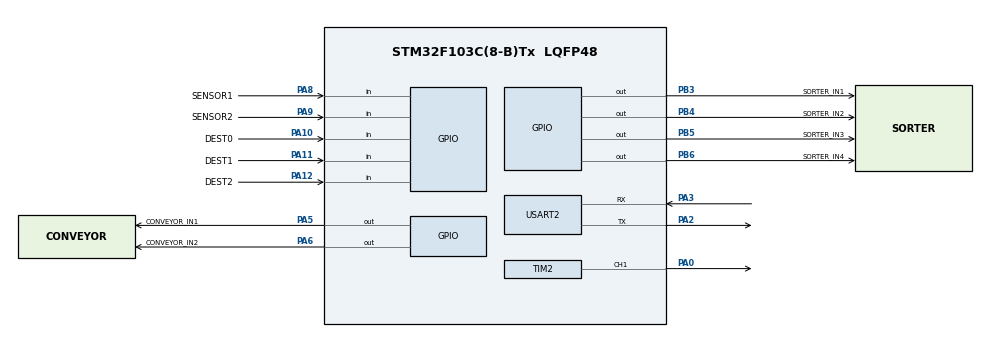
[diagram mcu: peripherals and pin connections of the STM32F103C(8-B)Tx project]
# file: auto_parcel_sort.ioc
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Dma.Request0=USART2_RX
Dma.USART2_RX.0.Direction=DMA_PERIPH_TO_MEMORY
Dma.USART2_RX.0.Instance=DMA1_Channel6
Dma.USART2_RX.0.MemDataAlignment=DMA_MDATAALIGN_BYTE
Dma.USART2_RX.0.MemInc=DMA_MINC_ENABLE
Dma.USART2_RX.0.Mode=DMA_NORMAL
Dma.USART2_RX.0.PeriphDataAlignment=DMA_PDATAALIGN_BYTE
Dma.USART2_RX.0.PeriphInc=DMA_PINC_DISABLE
Dma.USART2_RX.0.Priority=DMA_PRIORITY_LOW
FREERTOS.Queues01=eventQueue,16,uint16_t,0,Dynamic,NULL,NULL
FREERTOS.Tasks01=HWUpdateTask,26,128,hwUpdateEntryFunc,Default,NULL,Dynamic,NULL,NULL;LogicTask,25,128,logicTaskEntryFunc,Default,NULL,Dynamic,NULL,NULL
FREERTOS.configUSE_NEWLIB_REENTRANT=1
Mcu.Family=STM32F1
Mcu.Name=STM32F103C(8-B)Tx
Mcu.Package=LQFP48
NVIC.DMA1_Channel6_IRQn=true\:5\:0\:false\:false\:true\:true\:false\:true\:true
NVIC.PriorityGroup=NVIC_PRIORITYGROUP_4
NVIC.TIM1_UP_IRQn=true\:15\:0\:false\:false\:true\:false\:false\:true\:true
NVIC.TimeBase=TIM1_UP_IRQn
NVIC.TimeBaseIP=TIM1
NVIC.USART2_IRQn=true\:5\:0\:false\:false\:true\:true\:true\:true\:true
PA0-WKUP.Signal=S_TIM2_CH1_ETR
PA10.GPIO_Label=DEST0
PA10.Signal=GPIO_Input
PA11.GPIO_Label=DEST1
PA11.Signal=GPIO_Input
PA12.GPIO_Label=DEST2
PA12.Signal=GPIO_Input
PA13.Signal=SYS_JTMS-SWDIO
PA14.Signal=SYS_JTCK-SWCLK
PA2.Mode=Asynchronous
PA2.Signal=USART2_TX
PA3.Mode=Asynchronous
PA3.Signal=USART2_RX
PA5.GPIO_Label=CONVEYOR_IN1
PA5.Signal=GPIO_Output
PA6.GPIO_Label=CONVEYOR_IN2
PA6.Signal=GPIO_Output
PA8.GPIO_Label=SENSOR1
PA8.Signal=GPIO_Input
PA9.GPIO_Label=SENSOR2
PA9.Signal=GPIO_Input
PB3.GPIO_Label=SORTER_IN1
PB3.Signal=GPIO_Output
PB4.GPIO_Label=SORTER_IN2
PB4.Signal=GPIO_Output
PB5.GPIO_Label=SORTER_IN3
PB5.Signal=GPIO_Output
PB6.GPIO_Label=SORTER_IN4
PB6.Signal=GPIO_Output
ProjectManager.HeapSize=0x200
ProjectManager.StackSize=0x400
ProjectManager.TargetToolchain=STM32CubeIDE
RCC.APB1Freq_Value=8000000
RCC.APB2Freq_Value=8000000
SH.S_TIM2_CH1_ETR.0=TIM2_CH1,PWM Generation1 CH1
TIM2.Channel-PWM\ Generation1\ CH1=TIM_CHANNEL_1
TIM2.Period=1000-1
TIM2.Prescaler=84-1
USART2.VirtualMode=VM_ASYNC
VP_FREERTOS_VS_CMSIS_V2.Mode=CMSIS_V2
VP_SYS_VS_ND.Mode=No_Debug
VP_SYS_VS_tim1.Mode=TIM1
VP_TIM2_VS_ClockSourceINT.Mode=Internal
board=custom

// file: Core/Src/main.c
/* USER CODE BEGIN Header */
/**
  ******************************************************************************
  * @file           : main.c
  * @brief          : Main program body
  ******************************************************************************
  * @attention
  *
  * Copyright (c) 2025 STMicroelectronics.
  * All rights reserved.
  *
  * This software is licensed under terms that can be found in the LICENSE file
  * in the root directory of this software component.
  * If no LICENSE file comes with this software, it is provided AS-IS.
  *
  ******************************************************************************
  */
/* USER CODE END Header */
#include "main.h"
#include <string.h>

/* USER CODE BEGIN Includes */
#ifdef __cplusplus
extern "C" {
#endif
void Application_main();
#ifdef __cplusplus
}
#endif
/* USER CODE END Includes */

TIM_HandleTypeDef htim2;

UART_HandleTypeDef huart2;
DMA_HandleTypeDef hdma_usart2_rx;

void SystemClock_Config(void);
static void MX_GPIO_Init(void);
static void MX_DMA_Init(void);
static void MX_TIM2_Init(void);
static void MX_USART2_UART_Init(void);

int main(void)
{

  /* MCU Configuration--------------------------------------------------------*/

  /* Reset of all peripherals, Initializes the Flash interface and the Systick. */
  HAL_Init();

  /* Configure the system clock */
  SystemClock_Config();

  /* Initialize all configured peripherals */
  MX_GPIO_Init();
  MX_DMA_Init();
  MX_TIM2_Init();
  MX_USART2_UART_Init();
  /* USER CODE BEGIN 2 */
  HAL_UART_Transmit(&huart2, (uint8_t*)"main.c: Before osKernelInitialize\n", strlen("main.c: Before osKernelInitialize\n"), 100);
  osKernelInitialize();
  HAL_UART_Transmit(&huart2, (uint8_t*)"main.c: Before Application_main\n", strlen("main.c: Before Application_main\n"), 100);

  Application_main();

  HAL_UART_Transmit(&huart2, (uint8_t*)"main.c: After Application_main, before osKernelStart\n", strlen("main.c: After Application_main, before osKernelStart\n"), 100);
  osKernelStart();
  HAL_UART_Transmit(&huart2, (uint8_t*)"main.c: This should not be printed!\n", strlen("main.c: This should not be printed!\n"), 100);
  /* USER CODE END 2 */

  /* Infinite loop */
  while (1)
  {

  }
}

void SystemClock_Config(void)
{
  RCC_OscInitTypeDef RCC_OscInitStruct = {0};
  RCC_ClkInitTypeDef RCC_ClkInitStruct = {0};

  /** Initializes the RCC Oscillators according to the specified parameters
  * in the RCC_OscInitTypeDef structure.
  */
  RCC_OscInitStruct.OscillatorType = RCC_OSCILLATORTYPE_HSI;
  RCC_OscInitStruct.HSIState = RCC_HSI_ON;
  RCC_OscInitStruct.HSICalibrationValue = RCC_HSICALIBRATION_DEFAULT;
  RCC_OscInitStruct.PLL.PLLState = RCC_PLL_NONE;
  if (HAL_RCC_OscConfig(&RCC_OscInitStruct) != HAL_OK)
  {
    Error_Handler();
  }

  /** Initializes the CPU, AHB and APB buses clocks
  */
  RCC_ClkInitStruct.ClockType = RCC_CLOCKTYPE_HCLK|RCC_CLOCKTYPE_SYSCLK
                              |RCC_CLOCKTYPE_PCLK1|RCC_CLOCKTYPE_PCLK2;
  RCC_ClkInitStruct.SYSCLKSource = RCC_SYSCLKSOURCE_HSI;
  RCC_ClkInitStruct.AHBCLKDivider = RCC_SYSCLK_DIV1;
  RCC_ClkInitStruct.APB1CLKDivider = RCC_HCLK_DIV1;
  RCC_ClkInitStruct.APB2CLKDivider = RCC_HCLK_DIV1;

  if (HAL_RCC_ClockConfig(&RCC_ClkInitStruct, FLASH_LATENCY_0) != HAL_OK)
  {
    Error_Handler();
  }
}

static void MX_TIM2_Init(void)
{

  TIM_ClockConfigTypeDef sClockSourceConfig = {0};
  TIM_MasterConfigTypeDef sMasterConfig = {0};
  TIM_OC_InitTypeDef sConfigOC = {0};

  htim2.Instance = TIM2;
  htim2.Init.Prescaler = 84-1;
  htim2.Init.CounterMode = TIM_COUNTERMODE_UP;
  htim2.Init.Period = 1000-1;
  htim2.Init.ClockDivision = TIM_CLOCKDIVISION_DIV1;
  htim2.Init.AutoReloadPreload = TIM_AUTORELOAD_PRELOAD_DISABLE;
  if (HAL_TIM_Base_Init(&htim2) != HAL_OK)
  {
    Error_Handler();
  }
  sClockSourceConfig.ClockSource = TIM_CLOCKSOURCE_INTERNAL;
  if (HAL_TIM_ConfigClockSource(&htim2, &sClockSourceConfig) != HAL_OK)
  {
    Error_Handler();
  }
  if (HAL_TIM_PWM_Init(&htim2) != HAL_OK)
  {
    Error_Handler();
  }
  sMasterConfig.MasterOutputTrigger = TIM_TRGO_RESET;
  sMasterConfig.MasterSlaveMode = TIM_MASTERSLAVEMODE_DISABLE;
  if (HAL_TIMEx_MasterConfigSynchronization(&htim2, &sMasterConfig) != HAL_OK)
  {
    Error_Handler();
  }
  sConfigOC.OCMode = TIM_OCMODE_PWM1;
  sConfigOC.Pulse = 0;
  sConfigOC.OCPolarity = TIM_OCPOLARITY_HIGH;
  sConfigOC.OCFastMode = TIM_OCFAST_DISABLE;
  if (HAL_TIM_PWM_ConfigChannel(&htim2, &sConfigOC, TIM_CHANNEL_1) != HAL_OK)
  {
    Error_Handler();
  }
  HAL_TIM_MspPostInit(&htim2);

}

static void MX_USART2_UART_Init(void)
{

  huart2.Instance = USART2;
  huart2.Init.BaudRate = 115200;
  huart2.Init.WordLength = UART_WORDLENGTH_8B;
  huart2.Init.StopBits = UART_STOPBITS_1;
  huart2.Init.Parity = UART_PARITY_NONE;
  huart2.Init.Mode = UART_MODE_TX_RX;
  huart2.Init.HwFlowCtl = UART_HWCONTROL_NONE;
  huart2.Init.OverSampling = UART_OVERSAMPLING_16;
  if (HAL_UART_Init(&huart2) != HAL_OK)
  {
    Error_Handler();
  }

}

static void MX_DMA_Init(void)
{

  /* DMA controller clock enable */
  __HAL_RCC_DMA1_CLK_ENABLE();

  /* DMA interrupt init */
  /* DMA1_Channel6_IRQn interrupt configuration */
  HAL_NVIC_SetPriority(DMA1_Channel6_IRQn, 5, 0);
  HAL_NVIC_EnableIRQ(DMA1_Channel6_IRQn);

}

static void MX_GPIO_Init(void)
{
  GPIO_InitTypeDef GPIO_InitStruct = {0};

  /* GPIO Ports Clock Enable */
  __HAL_RCC_GPIOA_CLK_ENABLE();
  __HAL_RCC_GPIOB_CLK_ENABLE();

  /*Configure GPIO pin Output Level */
  HAL_GPIO_WritePin(GPIOA, CONVEYOR_IN1_Pin|CONVEYOR_IN2_Pin, GPIO_PIN_RESET);

  /*Configure GPIO pin Output Level */
  HAL_GPIO_WritePin(GPIOB, SORTER_IN1_Pin|SORTER_IN2_Pin|SORTER_IN3_Pin|SORTER_IN4_Pin, GPIO_PIN_RESET);

  /*Configure GPIO pins : CONVEYOR_IN1_Pin CONVEYOR_IN2_Pin */
  GPIO_InitStruct.Pin = CONVEYOR_IN1_Pin|CONVEYOR_IN2_Pin;
  GPIO_InitStruct.Mode = GPIO_MODE_OUTPUT_PP;
  GPIO_InitStruct.Pull = GPIO_NOPULL;
  GPIO_InitStruct.Speed = GPIO_SPEED_FREQ_LOW;
  HAL_GPIO_Init(GPIOA, &GPIO_InitStruct);

  /*Configure GPIO pins : SENSOR1_Pin SENSOR2_Pin DEST0_Pin DEST1_Pin
                           DEST2_Pin */
  GPIO_InitStruct.Pin = SENSOR1_Pin|SENSOR2_Pin|DEST0_Pin|DEST1_Pin
                          |DEST2_Pin;
  GPIO_InitStruct.Mode = GPIO_MODE_INPUT;
  GPIO_InitStruct.Pull = GPIO_NOPULL;
  HAL_GPIO_Init(GPIOA, &GPIO_InitStruct);

  /*Configure GPIO pins : SORTER_IN1_Pin SORTER_IN2_Pin SORTER_IN3_Pin SORTER_IN4_Pin */
  GPIO_InitStruct.Pin = SORTER_IN1_Pin|SORTER_IN2_Pin|SORTER_IN3_Pin|SORTER_IN4_Pin;
  GPIO_InitStruct.Mode = GPIO_MODE_OUTPUT_PP;
  GPIO_InitStruct.Pull = GPIO_NOPULL;
  GPIO_InitStruct.Speed = GPIO_SPEED_FREQ_LOW;
  HAL_GPIO_Init(GPIOB, &GPIO_InitStruct);

}

void HAL_TIM_PeriodElapsedCallback(TIM_HandleTypeDef *htim)
{
  if (htim->Instance == TIM1)
  {
    HAL_IncTick();
  }
}

void Error_Handler(void)
{
  __disable_irq();
  while (1)
  {
  }
}
